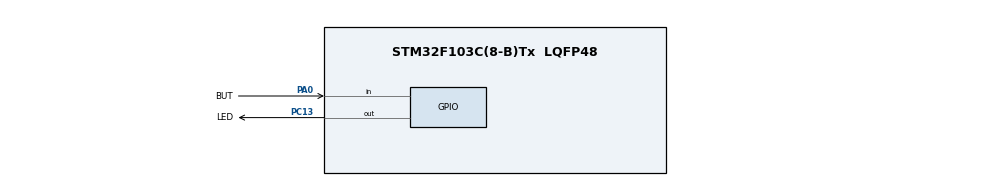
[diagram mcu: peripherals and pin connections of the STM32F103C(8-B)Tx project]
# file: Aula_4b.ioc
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Mcu.Family=STM32F1
Mcu.Name=STM32F103C(8-B)Tx
Mcu.Package=LQFP48
NVIC.PriorityGroup=NVIC_PRIORITYGROUP_4
PA0-WKUP.GPIO_Label=BUT
PA0-WKUP.GPIO_PuPd=GPIO_PULLDOWN
PA0-WKUP.Signal=GPIO_Input
PA13.Mode=Serial_Wire
PA13.Signal=SYS_JTMS-SWDIO
PA14.Mode=Serial_Wire
PA14.Signal=SYS_JTCK-SWCLK
PC13-TAMPER-RTC.GPIO_Label=LED
PC13-TAMPER-RTC.Signal=GPIO_Output
PD0-OSC_IN.Mode=HSE-External-Oscillator
PD0-OSC_IN.Signal=RCC_OSC_IN
PD1-OSC_OUT.Mode=HSE-External-Oscillator
PD1-OSC_OUT.Signal=RCC_OSC_OUT
ProjectManager.HeapSize=0x200
ProjectManager.StackSize=0x400
ProjectManager.TargetToolchain=STM32CubeIDE
RCC.APB1Freq_Value=8000000
RCC.APB2Freq_Value=8000000
RCC.SYSCLKSource=RCC_SYSCLKSOURCE_HSE
board=custom

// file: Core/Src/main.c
/* USER CODE BEGIN Header */
/**
  ******************************************************************************
  * @file           : main.c
  * @brief          : Main program body
  ******************************************************************************
  * @attention
  *
  * Copyright (c) 2025 STMicroelectronics.
  * All rights reserved.
  *
  * This software is licensed under terms that can be found in the LICENSE file
  * in the root directory of this software component.
  * If no LICENSE file comes with this software, it is provided AS-IS.
  *
  ******************************************************************************
  */
/* USER CODE END Header */
#include "main.h"

/* USER CODE BEGIN PD */
#define DEB_DELAY 50
/* USER CODE END PD */

void SystemClock_Config(void);
static void MX_GPIO_Init(void);
/* USER CODE BEGIN PFP */
uint8_t debounce(GPIO_TypeDef *GPIOx, uint16_t GPIO_Pin);
void delay_eng421(uint32_t tempo_ms);
int soma(int a, int b);
/* USER CODE END PFP */

int main(void)
{

  /* MCU Configuration--------------------------------------------------------*/

  /* Reset of all peripherals, Initializes the Flash interface and the Systick. */
  HAL_Init();

  /* Configure the system clock */
  SystemClock_Config();

  /* Initialize all configured peripherals */
  MX_GPIO_Init();

  /* Infinite loop */
  /* USER CODE BEGIN WHILE */
  while (1)
  {
	if(debounce(BUT_GPIO_Port, BUT_Pin))
	{
	  int vezes = soma(2, 5);
	  for(uint8_t i = 0; i < vezes * 2; i++)
	  {
	  	HAL_GPIO_TogglePin(LED_GPIO_Port, LED_Pin);
	  	delay_eng421(500);
	  }
	  while(HAL_GPIO_ReadPin(BUT_GPIO_Port, BUT_Pin) == 1);
	}
    /* USER CODE END WHILE */

  }
}

void SystemClock_Config(void)
{
  RCC_OscInitTypeDef RCC_OscInitStruct = {0};
  RCC_ClkInitTypeDef RCC_ClkInitStruct = {0};

  /** Initializes the RCC Oscillators according to the specified parameters
  * in the RCC_OscInitTypeDef structure.
  */
  RCC_OscInitStruct.OscillatorType = RCC_OSCILLATORTYPE_HSE;
  RCC_OscInitStruct.HSEState = RCC_HSE_ON;
  RCC_OscInitStruct.PLL.PLLState = RCC_PLL_NONE;
  if (HAL_RCC_OscConfig(&RCC_OscInitStruct) != HAL_OK)
  {
    Error_Handler();
  }

  /** Initializes the CPU, AHB and APB buses clocks
  */
  RCC_ClkInitStruct.ClockType = RCC_CLOCKTYPE_HCLK|RCC_CLOCKTYPE_SYSCLK
                              |RCC_CLOCKTYPE_PCLK1|RCC_CLOCKTYPE_PCLK2;
  RCC_ClkInitStruct.SYSCLKSource = RCC_SYSCLKSOURCE_HSE;
  RCC_ClkInitStruct.AHBCLKDivider = RCC_SYSCLK_DIV1;
  RCC_ClkInitStruct.APB1CLKDivider = RCC_HCLK_DIV1;
  RCC_ClkInitStruct.APB2CLKDivider = RCC_HCLK_DIV1;

  if (HAL_RCC_ClockConfig(&RCC_ClkInitStruct, FLASH_LATENCY_0) != HAL_OK)
  {
    Error_Handler();
  }
}

static void MX_GPIO_Init(void)
{
  GPIO_InitTypeDef GPIO_InitStruct = {0};

  /* GPIO Ports Clock Enable */
  __HAL_RCC_GPIOC_CLK_ENABLE();
  __HAL_RCC_GPIOD_CLK_ENABLE();
  __HAL_RCC_GPIOA_CLK_ENABLE();

  /*Configure GPIO pin Output Level */
  HAL_GPIO_WritePin(LED_GPIO_Port, LED_Pin, GPIO_PIN_RESET);

  /*Configure GPIO pin : LED_Pin */
  GPIO_InitStruct.Pin = LED_Pin;
  GPIO_InitStruct.Mode = GPIO_MODE_OUTPUT_PP;
  GPIO_InitStruct.Pull = GPIO_NOPULL;
  GPIO_InitStruct.Speed = GPIO_SPEED_FREQ_LOW;
  HAL_GPIO_Init(LED_GPIO_Port, &GPIO_InitStruct);

  /*Configure GPIO pin : BUT_Pin */
  GPIO_InitStruct.Pin = BUT_Pin;
  GPIO_InitStruct.Mode = GPIO_MODE_INPUT;
  GPIO_InitStruct.Pull = GPIO_PULLDOWN;
  HAL_GPIO_Init(BUT_GPIO_Port, &GPIO_InitStruct);

}

/* USER CODE BEGIN 4 */
void delay_eng421(uint32_t tempo_ms)
{
  uint32_t contagem_atual = HAL_GetTick();
  while((HAL_GetTick() - contagem_atual) < tempo_ms);
}

uint8_t debounce(GPIO_TypeDef *GPIOx, uint16_t GPIO_Pin)
{
  if(HAL_GPIO_ReadPin(GPIOx, GPIO_Pin) == 1)
  {
	  HAL_Delay(DEB_DELAY);
	  if(HAL_GPIO_ReadPin(GPIOx, GPIO_Pin) == 1)
	  {
		  return 1;
	  }
  }
  return 0;
}

int soma(int a, int b)
{
  return a + b;
}
/* USER CODE END 4 */

void Error_Handler(void)
{
  __disable_irq();
  while (1)
  {
  }
}
